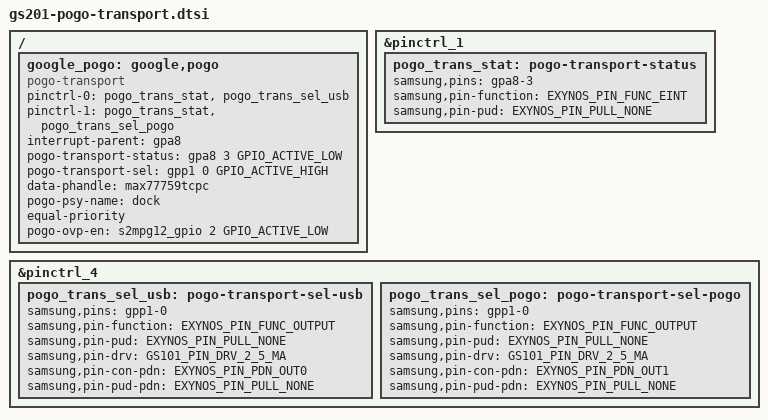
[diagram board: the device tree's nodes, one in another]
// SPDX-License-Identifier: GPL-2.0-only
/*
 * Google GS201 Pogo transport
 *
 * Copyright (c) 2022 Google, LLC
 *
 */
#include <dt-bindings/gpio/gpio.h>
#include <dt-bindings/pinctrl/samsung.h>

/ {
	fragment@pogo_transport {
		target-path = "/";
		__overlay__ {

			google_pogo: google,pogo {
				status = "okay";
				compatible = "pogo-transport";
				pinctrl-names = "suspend-to-usb", "suspend-to-pogo";
				pinctrl-0 = <&pogo_trans_stat &pogo_trans_sel_usb>;
				pinctrl-1 = <&pogo_trans_stat &pogo_trans_sel_pogo>;
				interrupt-parent = <&gpa8>;
				pogo-transport-status = <&gpa8 3 GPIO_ACTIVE_LOW>;
				pogo-transport-sel = <&gpp1 0 GPIO_ACTIVE_HIGH>;
				data-phandle = <&max77759tcpc>;
				pogo-psy-name = "dock";
				equal-priority;
				pogo-ovp-en = <&s2mpg12_gpio 2 GPIO_ACTIVE_LOW>;
			};
		};
	};
};

/* GPIO_FAR_ALIVE */
&pinctrl_1 {
	pogo_trans_stat: pogo-transport-status {
		samsung,pins = "gpa8-3";
		samsung,pin-function = <EXYNOS_PIN_FUNC_EINT>;
		samsung,pin-pud = <EXYNOS_PIN_PULL_NONE>;
	};
};

/* GPIO_PERIC0 */
&pinctrl_4 {
	pogo_trans_sel_usb: pogo-transport-sel-usb {
		samsung,pins = "gpp1-0";
		samsung,pin-function = <EXYNOS_PIN_FUNC_OUTPUT>;
		samsung,pin-pud = <EXYNOS_PIN_PULL_NONE>;
		samsung,pin-drv = <GS101_PIN_DRV_2_5_MA>;
		samsung,pin-con-pdn = <EXYNOS_PIN_PDN_OUT0>;
		samsung,pin-pud-pdn = <EXYNOS_PIN_PULL_NONE>;
	};

	pogo_trans_sel_pogo: pogo-transport-sel-pogo {
		samsung,pins = "gpp1-0";
		samsung,pin-function = <EXYNOS_PIN_FUNC_OUTPUT>;
		samsung,pin-pud = <EXYNOS_PIN_PULL_NONE>;
		samsung,pin-drv = <GS101_PIN_DRV_2_5_MA>;
		samsung,pin-con-pdn = <EXYNOS_PIN_PDN_OUT1>;
		samsung,pin-pud-pdn = <EXYNOS_PIN_PULL_NONE>;
	};
};
